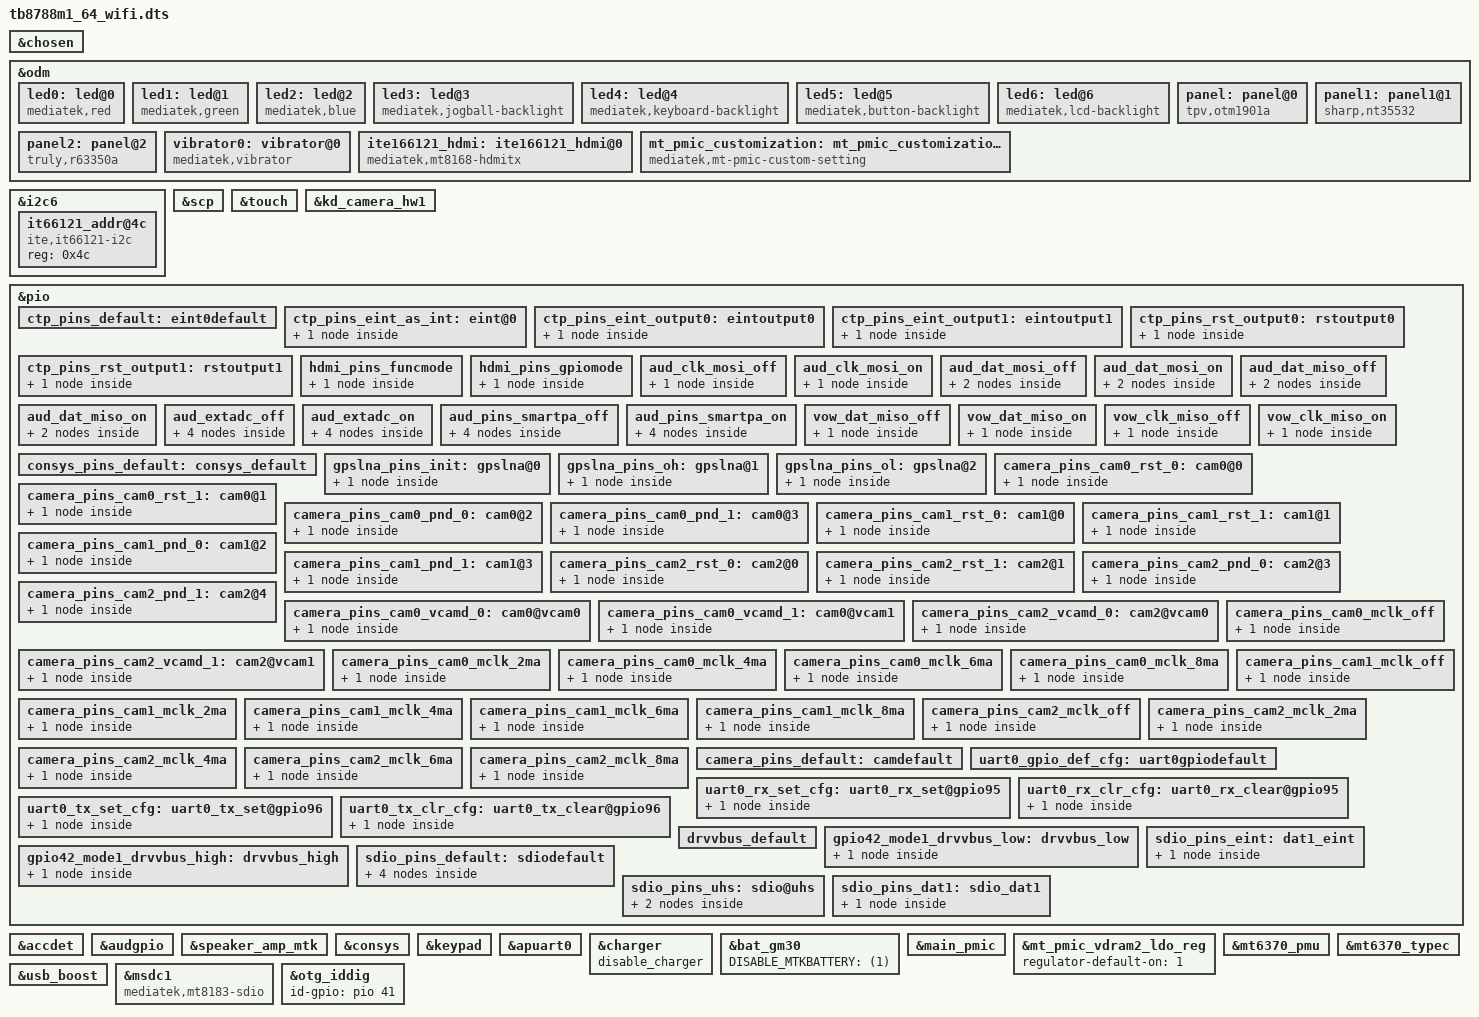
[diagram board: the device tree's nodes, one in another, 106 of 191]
/*
 * Copyright (C) 2019 MediaTek Inc.
 *
 * This program is free software; you can redistribute it and/or modify
 * it under the terms of the GNU General Public License version 2 as
 * published by the Free Software Foundation.
 *
 * This program is distributed in the hope that it will be useful,
 * but WITHOUT ANY WARRANTY; without even the implied warranty of
 * MERCHANTABILITY or FITNESS FOR A PARTICULAR PURPOSE.
 * See http://www.gnu.org/licenses/gpl-2.0.html for more details.
 */

/dts-v1/;
/plugin/;
#include <dt-bindings/interrupt-controller/irq.h>
#include <dt-bindings/interrupt-controller/arm-gic.h>
#include <dt-bindings/pinctrl/mt6771-pinfunc.h>
#include <dt-bindings/clock/mt6771-clk.h>
#include <tb8788m1_64_wifi/cust.dtsi>

/* chosen */
&chosen {
	/* fpga may has no lk, we need to specify display info here */
	/* fb buffer is reserved using this dts by memory node above */

	atag,videolfb-fb_base_l = <0x5e605000>;
	atag,videolfb-fb_base_h = <0x0>;
	atag,videolfb-islcmfound = <1>;
	atag,videolfb-islcm_inited = <0>;
	atag,videolfb-fps= <6000>;
	atag,videolfb-vramSize= <0x017bb000>;
	atag,videolfb-lcmname= "otm1901a_fhd_dsi_vdo_tpv
		r63350a_fhd_dsi_vdo_truly nt35532_fhd_dsi_vdo_sharp";
};

&odm {
	led0:led@0 {
		compatible = "mediatek,red";
		led_mode = <0>;
		data = <1>;
		pwm_config = <0 0 0 0 0>;
	};
	led1:led@1 {
		compatible = "mediatek,green";
		led_mode = <0>;
		data = <1>;
		pwm_config = <0 0 0 0 0>;
	};
	led2:led@2 {
		compatible = "mediatek,blue";
		led_mode = <0>;
		data = <1>;
		pwm_config = <0 0 0 0 0>;
	};
	led3:led@3 {
		compatible = "mediatek,jogball-backlight";
		led_mode = <0>;
		data = <1>;
		pwm_config = <0 0 0 0 0>;
	};
	led4:led@4 {
		compatible = "mediatek,keyboard-backlight";
		led_mode = <0>;
		data = <1>;
		pwm_config = <0 0 0 0 0>;
	};
	led5:led@5 {
		compatible = "mediatek,button-backlight";
		led_mode = <0>;
		data = <1>;
		pwm_config = <0 0 0 0 0>;
	};
	led6:led@6 {
		compatible = "mediatek,lcd-backlight";
		led_mode = <5>;
		data = <1>;
		pwm_config = <0 1 0 0 0>;
	};
	panel: panel@0 {
		compatible = "tpv,otm1901a";
		gpio_lcd_rst = <&pio 45 0>;
		gpio_lcd_pwr_en = <&pio 158 0>;
		gpio_lcd_pwr2_en = <&pio 159 0>;
		gpio_lcd_pwr = <&pio 153 0>;
		status = "okay";
	};
	panel1: panel1@1 {
		compatible = "sharp,nt35532";
		gpio_lcd_rst = <&pio 45 0>;
		gpio_lcd_pwr_en = <&pio 158 0>;
		gpio_lcd_pwr2_en = <&pio 159 0>;
		gpio_lcd_pwr = <&pio 153 0>;
		status = "okay";
	};
	panel2: panel@2 {
		compatible = "truly,r63350a";
		gpio_lcd_rst = <&pio 45 0>;
		gpio_lcd_pwr_en = <&pio 158 0>;
		gpio_lcd_pwr2_en = <&pio 159 0>;
		gpio_lcd_pwr = <&pio 153 0>;
		status = "okay";
	};
	vibrator0:vibrator@0 {
		compatible = "mediatek,vibrator";
		vib_timer = <25>;
		vib_limit = <9>;
		vib_vol= <9>;
	};
	ite166121_hdmi: ite166121_hdmi@0 {
		compatible = "mediatek,mt8168-hdmitx";
	};
	mt_pmic_customization: mt_pmic_customization@0 {
		compatible = "mediatek,mt-pmic-custom-setting";
		custom-reg = <0x1c32 0x1 0x7 0x0 /* LDO_VRF12_OP_EN */
			      0x18ba 0x1 0x1 0x0 /* RG_VPA_NDIS_EN */
		>;
		disable-modem = <1>;
	};
};


&ite166121_hdmi {
	pinctrl-names = "hdmi_poweron", "hdmi_poweroff";
	pinctrl-0 = <&hdmi_pins_funcmode>;
	pinctrl-1 = <&hdmi_pins_gpiomode>;
	vcn33-supply = <&mt_pmic_vcn33_wifi_ldo_reg>;
	vcn18-supply = <&mt_pmic_vcn18_ldo_reg>;
	vrf12-supply = <&mt_pmic_vrf12_ldo_reg>;
	hdmi_power_gpios = <&pio 160 0>;
	status = "okay";
};

&i2c6 {
	status = "okay";
	it66121_addr@4c {
		compatible = "ite,it66121-i2c";
		reg = <0x4c>;
	};
};

&scp {
	core_1 = "enable";
	scp_sramSize = <0x00080000>;     /* scp_A_sram_size */
};

/* TOUCH start */
&touch {
	tpd-resolution = <1080 1920>;
	use-tpd-button = <0>;
	tpd-key-num = <3>;
	tpd-key-local= <139 172 158 0>;
	tpd-key-dim-local = <90 883 100 40
		230 883 100 40 370 883 100 40 0 0 0 0>;
	tpd-max-touch-num = <5>;
	tpd-filter-enable = <1>;
	tpd-filter-pixel-density = <146>;
	tpd-filter-custom-prameters = <0 0 0 0 0 0 0 0 0 0 0 0>;
	tpd-filter-custom-speed = <0 0 0>;
	pinctrl-names = "default", "state_eint_as_int",
		"state_eint_output0", "state_eint_output1",
		"state_rst_output0", "state_rst_output1";
	pinctrl-0 = <&ctp_pins_default>;
	pinctrl-1 = <&ctp_pins_eint_as_int>;
	pinctrl-2 = <&ctp_pins_eint_output0>;
	pinctrl-3 = <&ctp_pins_eint_output1>;
	pinctrl-4 = <&ctp_pins_rst_output0>;
	pinctrl-5 = <&ctp_pins_rst_output1>;
	status = "okay";
};

/* CAMERA specify sensor */
&kd_camera_hw1 {
	cam0_enable_sensor = "ov13855_mipi_raw";
	cam2_enable_sensor = "ov13855main2_mipi_raw";
};
/* CAMERA specify sensor end */

&pio {
	ctp_pins_default: eint0default {
	};
	ctp_pins_eint_as_int: eint@0 {
		pins_cmd_dat {
			pinmux = <PINMUX_GPIO176__FUNC_GPIO176>;
			slew-rate = <0>;
			bias-disable;
		};
	};
	ctp_pins_eint_output0: eintoutput0 {
		pins_cmd_dat {
			pinmux = <PINMUX_GPIO176__FUNC_GPIO176>;
			slew-rate = <1>;
			output-low;
		};
	};
	ctp_pins_eint_output1: eintoutput1 {
		pins_cmd_dat {
			pinmux = <PINMUX_GPIO176__FUNC_GPIO176>;
			slew-rate = <1>;
			output-high;
		};
	};
	ctp_pins_rst_output0: rstoutput0 {
		pins_cmd_dat {
			pinmux = <PINMUX_GPIO177__FUNC_GPIO177>;
			slew-rate = <1>;
			output-low;
		};
	};
	ctp_pins_rst_output1: rstoutput1 {
		pins_cmd_dat {
			pinmux = <PINMUX_GPIO177__FUNC_GPIO177>;
			slew-rate = <1>;
			output-high;
		};
	};
	hdmi_pins_funcmode: hdmi_pins_funcmode {
		pins_cmd_dat {
			pinmux = <PINMUX_GPIO113__FUNC_SCL6>,
				<PINMUX_GPIO114__FUNC_SDA6>,
				<PINMUX_GPIO12__FUNC_I2S5_BCK>,
				<PINMUX_GPIO46__FUNC_I2S5_LRCK>,
				<PINMUX_GPIO47__FUNC_I2S5_DO>,
				<PINMUX_GPIO13__FUNC_DBPI_D0>,
				<PINMUX_GPIO14__FUNC_DBPI_D1>,
				<PINMUX_GPIO15__FUNC_DBPI_D2>,
				<PINMUX_GPIO16__FUNC_DBPI_D3>,
				<PINMUX_GPIO17__FUNC_DBPI_D4>,
				<PINMUX_GPIO18__FUNC_DBPI_D5>,
				<PINMUX_GPIO19__FUNC_DBPI_D6>,
				<PINMUX_GPIO20__FUNC_DBPI_D7>,
				<PINMUX_GPIO21__FUNC_DBPI_D8>,
				<PINMUX_GPIO22__FUNC_DBPI_D9>,
				<PINMUX_GPIO23__FUNC_DBPI_D10>,
				<PINMUX_GPIO24__FUNC_DBPI_D11>,
				<PINMUX_GPIO25__FUNC_DBPI_HSYNC>,
				<PINMUX_GPIO26__FUNC_DBPI_VSYNC>,
				<PINMUX_GPIO27__FUNC_DBPI_DE>,
				<PINMUX_GPIO28__FUNC_DBPI_CK>;
		};
	};
	hdmi_pins_gpiomode: hdmi_pins_gpiomode {
		pins_cmd_dat {
			pinmux = <PINMUX_GPIO113__FUNC_GPIO113>,
				<PINMUX_GPIO114__FUNC_GPIO114>,
				<PINMUX_GPIO12__FUNC_GPIO12>,
				<PINMUX_GPIO46__FUNC_GPIO46>,
				<PINMUX_GPIO47__FUNC_GPIO47>,
				<PINMUX_GPIO13__FUNC_GPIO13>,
				<PINMUX_GPIO14__FUNC_GPIO14>,
				<PINMUX_GPIO15__FUNC_GPIO15>,
				<PINMUX_GPIO16__FUNC_GPIO16>,
				<PINMUX_GPIO17__FUNC_GPIO17>,
				<PINMUX_GPIO18__FUNC_GPIO18>,
				<PINMUX_GPIO19__FUNC_GPIO19>,
				<PINMUX_GPIO20__FUNC_GPIO20>,
				<PINMUX_GPIO21__FUNC_GPIO21>,
				<PINMUX_GPIO22__FUNC_GPIO22>,
				<PINMUX_GPIO23__FUNC_GPIO23>,
				<PINMUX_GPIO24__FUNC_GPIO24>,
				<PINMUX_GPIO25__FUNC_GPIO25>,
				<PINMUX_GPIO26__FUNC_GPIO26>,
				<PINMUX_GPIO27__FUNC_GPIO27>,
				<PINMUX_GPIO28__FUNC_GPIO28>;
		};
	};
};
/* TOUCH end */

/* accdet start */
&accdet {
	/* accdet micbias voltage: 0x07,2.7v;0x05,2.5v;0x02,1.9v */
	accdet-mic-vol = <6>;
	headset-mode-setting = <0x500 0x500 1 0x1f0 0x800 0x800 0x20 0x44>;
	accdet-plugout-debounce = <1>;
	/*1:ACC mode, 2:low cost without in bias, 6:low cost with in bias*/
	accdet-mic-mode = <2>;
	/* eint_level_trigger: 8,LEVEL_LOW(default);*/
	/* 4,LEVEL_HIGH;others,LEVEL_LOW */
	headset-eint-level-pol = <4>;
	/*0--MD_MAX--UP_MAX--DW_MAX*/
	headset-three-key-threshold = <0 80 220 400>;
	headset-three-key-threshold-CDD = <0 121 192 600>;
	/*0--MD_MAX--VOICE_MAX--UP_MAX--DW_MAX*/
	headset-four-key-threshold = <0 58 121 192 400>;
	status = "okay";
};
/* accdet end */

/* AUDIO GPIO standardization */
&audgpio {
	pinctrl-names = "aud_clk_mosi_off",
			"aud_clk_mosi_on",
			"aud_dat_mosi_off",
			"aud_dat_mosi_on",
			"aud_dat_miso_off",
			"aud_dat_miso_on",
			"aud_extadc_off",
			"aud_extadc_on",
			"aud_smartpa_off",
			"aud_smartpa_on",
			"vow_dat_miso_off",
			"vow_dat_miso_on",
			"vow_clk_miso_off",
			"vow_clk_miso_on";
	pinctrl-0 = <&aud_clk_mosi_off>;
	pinctrl-1 = <&aud_clk_mosi_on>;
	pinctrl-2 = <&aud_dat_mosi_off>;
	pinctrl-3 = <&aud_dat_mosi_on>;
	pinctrl-4 = <&aud_dat_miso_off>;
	pinctrl-5 = <&aud_dat_miso_on>;
	pinctrl-6 = <&aud_extadc_off>;
	pinctrl-7 = <&aud_extadc_on>;
	pinctrl-8 = <&aud_pins_smartpa_off>;
	pinctrl-9 = <&aud_pins_smartpa_on>;
	pinctrl-10 = <&vow_dat_miso_off>;
	pinctrl-11 = <&vow_dat_miso_on>;
	pinctrl-12 = <&vow_clk_miso_off>;
	pinctrl-13 = <&vow_clk_miso_on>;
	status = "okay";
};

&pio {
	aud_clk_mosi_off: aud_clk_mosi_off {
		pins_cmd0_dat {
			pinmux = <PINMUX_GPIO136__FUNC_GPIO136>;
		};
	};

	aud_clk_mosi_on: aud_clk_mosi_on {
		pins_cmd0_dat {
			pinmux = <PINMUX_GPIO136__FUNC_AUD_CLK_MOSI>;
		};
	};

	aud_dat_mosi_off: aud_dat_mosi_off {
		pins_cmd1_dat {
			pinmux = <PINMUX_GPIO138__FUNC_GPIO138>;
		};
		pins_cmd2_dat {
			pinmux = <PINMUX_GPIO139__FUNC_GPIO139>;
		};
	};

	aud_dat_mosi_on: aud_dat_mosi_on {
		pins_cmd1_dat {
			pinmux = <PINMUX_GPIO138__FUNC_AUD_DAT_MOSI0>;
		};
		pins_cmd2_dat {
			pinmux = <PINMUX_GPIO139__FUNC_AUD_DAT_MOSI1>;
		};
	};

	aud_dat_miso_off: aud_dat_miso_off {
		pins_cmd1_dat {
			pinmux = <PINMUX_GPIO142__FUNC_GPIO142>;
		};
		pins_cmd2_dat {
			pinmux = <PINMUX_GPIO143__FUNC_GPIO143>;
		};
	};

	aud_dat_miso_on: aud_dat_miso_on {
		pins_cmd1_dat {
			pinmux = <PINMUX_GPIO142__FUNC_AUD_DAT_MISO0>;
		};
		pins_cmd2_dat {
			pinmux = <PINMUX_GPIO143__FUNC_AUD_DAT_MISO1>;
		};
	};

	aud_extadc_off: aud_extadc_off {
		pins_cmd0_dat {
			pinmux = <PINMUX_GPIO98__FUNC_GPIO98>;
		};
		pins_cmd1_dat {
			pinmux = <PINMUX_GPIO101__FUNC_GPIO101>;
		};
		pins_cmd2_dat {
			pinmux = <PINMUX_GPIO102__FUNC_GPIO102>;
		};
		pins_cmd3_dat {
			pinmux = <PINMUX_GPIO174__FUNC_GPIO174>;
		};
	};

	aud_extadc_on: aud_extadc_on {
		pins_cmd0_dat {
			pinmux = <PINMUX_GPIO98__FUNC_I2S2_BCK>;
		};
		pins_cmd1_dat {
			pinmux = <PINMUX_GPIO101__FUNC_I2S2_LRCK>;
		};
		pins_cmd2_dat {
			pinmux = <PINMUX_GPIO102__FUNC_I2S2_DI>;
		};
		pins_cmd3_dat {
			pinmux = <PINMUX_GPIO174__FUNC_I2S2_DI2>;
		};
	};

	aud_pins_smartpa_off: aud_pins_smartpa_off {
		pins_cmd0_dat {
			pinmux = <PINMUX_GPIO170__FUNC_GPIO170>;
		};
		pins_cmd1_dat {
			pinmux = <PINMUX_GPIO171__FUNC_GPIO171>;
		};
		pins_cmd2_dat {
			pinmux = <PINMUX_GPIO172__FUNC_GPIO172>;
		};
		pins_cmd3_dat {
			pinmux = <PINMUX_GPIO173__FUNC_GPIO173>;
		};
	};

	aud_pins_smartpa_on: aud_pins_smartpa_on {
		pins_cmd0_dat {
			pinmux = <PINMUX_GPIO170__FUNC_I2S1_BCK>;
		};
		pins_cmd1_dat {
			pinmux = <PINMUX_GPIO171__FUNC_I2S1_LRCK>;
		};
		pins_cmd2_dat {
			pinmux= <PINMUX_GPIO172__FUNC_I2S1_DO>;
		};
		pins_cmd3_dat {
			pinmux = <PINMUX_GPIO173__FUNC_I2S1_MCK>;
		};
	};

	vow_dat_miso_off: vow_dat_miso_off {
		pins_cmd1_dat {
			pinmux = <PINMUX_GPIO142__FUNC_GPIO142>;
		};
	};

	vow_dat_miso_on: vow_dat_miso_on {
		pins_cmd1_dat {
			pinmux = <PINMUX_GPIO142__FUNC_VOW_DAT_MISO>;
		};
	};

	vow_clk_miso_off: vow_clk_miso_off {
		pins_cmd3_dat {
			pinmux = <PINMUX_GPIO143__FUNC_GPIO143>;
		};
	};

	vow_clk_miso_on: vow_clk_miso_on {
		pins_cmd3_dat {
			pinmux = <PINMUX_GPIO143__FUNC_VOW_CLK_MISO>;
		};
	};
};

&speaker_amp_mtk{
	rst_gpio = <&pio 151 0>;
	power_gpio = <&pio 150 0>;
};
/* AUDIO end */

/* CONSYS GPIO standardization */
&pio {
	consys_pins_default: consys_default {
	};
	gpslna_pins_init: gpslna@0 {
		pins_cmd_dat {
			pinmux = <PINMUX_GPIO155__FUNC_GPIO155>;
			slew-rate = <0>;
			bias-disable;
			output-low;
		};
	};
	gpslna_pins_oh: gpslna@1 {
		pins_cmd_dat {
			pinmux = <PINMUX_GPIO155__FUNC_GPIO155>;
			slew-rate = <1>;
			output-high;
		};
	};
	gpslna_pins_ol: gpslna@2 {
		pins_cmd_dat {
			pinmux = <PINMUX_GPIO155__FUNC_GPIO155>;
			slew-rate = <1>;
			output-low;
		};
	};
};
&consys {
	pinctrl-names = "default", "gps_lna_state_init",
		"gps_lna_state_oh", "gps_lna_state_ol";
	pinctrl-0 = <&consys_pins_default>;
	pinctrl-1 = <&gpslna_pins_init>;
	pinctrl-2 = <&gpslna_pins_oh>;
	pinctrl-3 = <&gpslna_pins_ol>;
	status = "okay";
};
/* CONSYS end */

/* CAMERA GPIO standardization */
&pio {
	camera_pins_cam0_rst_0: cam0@0 {
		pins_cmd_dat {
			pinmux = <PINMUX_GPIO37__FUNC_GPIO37>;
			slew-rate = <1>; /*direction 0:in, 1:out*/
			output-low;/*direction out used only.*/
					/*output_low or high*/
		};
	};
	camera_pins_cam0_rst_1: cam0@1 {
		pins_cmd_dat {
			pinmux = <PINMUX_GPIO37__FUNC_GPIO37>;
			slew-rate = <1>;
			output-high;
		};
	};
	camera_pins_cam0_pnd_0: cam0@2 {
		pins_cmd_dat {
			pinmux = <PINMUX_GPIO35__FUNC_GPIO35>;
			slew-rate = <1>;
			output-low;
		};
	};
	camera_pins_cam0_pnd_1: cam0@3 {
		pins_cmd_dat {
			pinmux = <PINMUX_GPIO35__FUNC_GPIO35>;
			slew-rate = <1>;
			output-high;
		};
	};
	camera_pins_cam1_rst_0: cam1@0 {
		pins_cmd_dat {
			pinmux = <PINMUX_GPIO36__FUNC_GPIO36>;
			slew-rate = <1>; /*direction 0:in, 1:out*/
			output-low;/*direction out used only.*/
					/*output_low or high*/
		};
	};
	camera_pins_cam1_rst_1: cam1@1 {
		pins_cmd_dat {
			pinmux = <PINMUX_GPIO36__FUNC_GPIO36>;
			slew-rate = <1>;
			output-high;
		};
	};
	camera_pins_cam1_pnd_0: cam1@2 {
		pins_cmd_dat {
			pinmux = <PINMUX_GPIO38__FUNC_GPIO38>;
			slew-rate = <1>;
			output-low;
		};
	};
	camera_pins_cam1_pnd_1: cam1@3 {
		pins_cmd_dat {
			pinmux = <PINMUX_GPIO38__FUNC_GPIO38>;
			slew-rate = <1>;
			output-high;
		};
	};
	camera_pins_cam2_rst_0: cam2@0 {
		pins_cmd_dat {
			pinmux = <PINMUX_GPIO109__FUNC_GPIO109>;
			slew-rate = <1>;
			output-low;
		};
	};
	camera_pins_cam2_rst_1: cam2@1 {
		pins_cmd_dat {
			pinmux = <PINMUX_GPIO109__FUNC_GPIO109>;
			slew-rate = <1>;
			output-high;
		};
	};
	camera_pins_cam2_pnd_0: cam2@3 {
		pins_cmd_dat {
			pinmux = <PINMUX_GPIO107__FUNC_GPIO107>;
			slew-rate = <1>;
			output-low;
		};
	};
	camera_pins_cam2_pnd_1: cam2@4 {
		pins_cmd_dat {
			pinmux = <PINMUX_GPIO107__FUNC_GPIO107>;
			slew-rate = <1>;
			output-high;
		};
	};
	camera_pins_cam0_vcamd_0: cam0@vcam0 {
		pins_cmd_dat {
			pinmux = <PINMUX_GPIO40__FUNC_GPIO40>;
			slew-rate = <1>;
			output-low;
		};
	};
	camera_pins_cam0_vcamd_1: cam0@vcam1 {
		pins_cmd_dat {
			pinmux = <PINMUX_GPIO40__FUNC_GPIO40>;
			slew-rate = <1>;
			output-high;
		};
	};
	camera_pins_cam2_vcamd_0: cam2@vcam0 {
		pins_cmd_dat {
			pinmux = <PINMUX_GPIO39__FUNC_GPIO39>;
			slew-rate = <1>;
			output-low;
		};
	};
	camera_pins_cam2_vcamd_1: cam2@vcam1 {
		pins_cmd_dat {
			pinmux = <PINMUX_GPIO39__FUNC_GPIO39>;
			slew-rate = <1>;
			output-high;
		};
	};
	camera_pins_cam0_mclk_off: camera_pins_cam0_mclk_off {
		pins_cmd_dat {
			pinmux = <PINMUX_GPIO99__FUNC_GPIO99>;
			drive-strength = <1>;
		};
	};
	camera_pins_cam0_mclk_2ma: camera_pins_cam0_mclk_2ma {
		pins_cmd_dat {
			pinmux = <PINMUX_GPIO99__FUNC_CMMCLK0>;
			drive-strength = <0>;
		};
	};
	camera_pins_cam0_mclk_4ma: camera_pins_cam0_mclk_4ma {
		pins_cmd_dat {
			pinmux = <PINMUX_GPIO99__FUNC_CMMCLK0>;
			drive-strength = <1>;
		};
	};
	camera_pins_cam0_mclk_6ma: camera_pins_cam0_mclk_6ma {
		pins_cmd_dat {
			pinmux = <PINMUX_GPIO99__FUNC_CMMCLK0>;
			drive-strength = <2>;
		};
	};
	camera_pins_cam0_mclk_8ma: camera_pins_cam0_mclk_8ma {
		pins_cmd_dat {
			pinmux = <PINMUX_GPIO99__FUNC_CMMCLK0>;
			drive-strength = <3>;
		};
	};
	camera_pins_cam1_mclk_off: camera_pins_cam1_mclk_off {
		pins_cmd_dat {
			pinmux = <PINMUX_GPIO100__FUNC_GPIO100>;
			drive-strength = <1>;
		};
	};
	camera_pins_cam1_mclk_2ma: camera_pins_cam1_mclk_2ma {
		pins_cmd_dat {
			pinmux = <PINMUX_GPIO100__FUNC_CMMCLK1>;
			drive-strength = <0>;
		};
	};
	camera_pins_cam1_mclk_4ma: camera_pins_cam1_mclk_4ma {
		pins_cmd_dat {
			pinmux = <PINMUX_GPIO100__FUNC_CMMCLK1>;
			drive-strength = <1>;
		};
	};
	camera_pins_cam1_mclk_6ma: camera_pins_cam1_mclk_6ma {
		pins_cmd_dat {
			pinmux = <PINMUX_GPIO100__FUNC_CMMCLK1>;
			drive-strength = <2>;
		};
	};
	camera_pins_cam1_mclk_8ma: camera_pins_cam1_mclk_8ma {
		pins_cmd_dat {
			pinmux = <PINMUX_GPIO100__FUNC_CMMCLK1>;
			drive-strength = <3>;
		};
	};
	camera_pins_cam2_mclk_off: camera_pins_cam2_mclk_off {
		pins_cmd_dat {
			pinmux = <PINMUX_GPIO108__FUNC_GPIO108>;
			drive-strength = <1>;
		};
	};
	camera_pins_cam2_mclk_2ma: camera_pins_cam2_mclk_2ma {
		pins_cmd_dat {
			pinmux = <PINMUX_GPIO108__FUNC_CMMCLK2>;
			drive-strength = <0>;
		};
	};
	camera_pins_cam2_mclk_4ma: camera_pins_cam2_mclk_4ma {
		pins_cmd_dat {
			pinmux = <PINMUX_GPIO108__FUNC_CMMCLK2>;
			drive-strength = <1>;
		};
	};
	camera_pins_cam2_mclk_6ma: camera_pins_cam2_mclk_6ma {
		pins_cmd_dat {
			pinmux = <PINMUX_GPIO108__FUNC_CMMCLK2>;
			drive-strength = <2>;
		};
	};
	camera_pins_cam2_mclk_8ma: camera_pins_cam2_mclk_8ma {
		pins_cmd_dat {
			pinmux = <PINMUX_GPIO108__FUNC_CMMCLK2>;
			drive-strength = <3>;
		};
	};
	camera_pins_default: camdefault {
	};
};
&kd_camera_hw1 {
	pinctrl-names = "default",
			"cam0_rst0", "cam0_rst1",
			"cam0_pnd0", "cam0_pnd1",
			"cam1_rst0", "cam1_rst1",
			"cam1_pnd0", "cam1_pnd1",
			"cam2_rst0", "cam2_rst1",
			"cam2_pnd0", "cam2_pnd1",
			"cam_ldo_vcamd_0", "cam_ldo_vcamd_1",
			"cam_ldo_main2_vcamd_0", "cam_ldo_main2_vcamd_1",
			"cam0_mclk_off",
			"cam0_mclk_2mA", "cam0_mclk_4mA",
			"cam0_mclk_6mA", "cam0_mclk_8mA",
			"cam1_mclk_off",
			"cam1_mclk_2mA", "cam1_mclk_4mA",
			"cam1_mclk_6mA", "cam1_mclk_8mA",
			"cam2_mclk_off",
			"cam2_mclk_2mA", "cam2_mclk_4mA",
			"cam2_mclk_6mA", "cam2_mclk_8mA";
	pinctrl-0 = <&camera_pins_default>;
	pinctrl-1 = <&camera_pins_cam0_rst_0>;
	pinctrl-2 = <&camera_pins_cam0_rst_1>;
	pinctrl-3 = <&camera_pins_cam0_pnd_0>;
	pinctrl-4 = <&camera_pins_cam0_pnd_1>;
	pinctrl-5 = <&camera_pins_cam1_rst_0>;
	pinctrl-6 = <&camera_pins_cam1_rst_1>;
	pinctrl-7 = <&camera_pins_cam1_pnd_0>;
	pinctrl-8 = <&camera_pins_cam1_pnd_1>;
	pinctrl-9 = <&camera_pins_cam2_rst_0>;
	pinctrl-10 = <&camera_pins_cam2_rst_1>;
	pinctrl-11 = <&camera_pins_cam2_pnd_0>;
	pinctrl-12 = <&camera_pins_cam2_pnd_1>;
	pinctrl-13 = <&camera_pins_cam0_vcamd_0>;
	pinctrl-14 = <&camera_pins_cam0_vcamd_1>;
	pinctrl-15 = <&camera_pins_cam2_vcamd_0>;
	pinctrl-16 = <&camera_pins_cam2_vcamd_1>;
	pinctrl-17 = <&camera_pins_cam0_mclk_off>;
	pinctrl-18 = <&camera_pins_cam0_mclk_2ma>;
	pinctrl-19 = <&camera_pins_cam0_mclk_4ma>;
	pinctrl-20 = <&camera_pins_cam0_mclk_6ma>;
	pinctrl-21 = <&camera_pins_cam0_mclk_8ma>;
	pinctrl-22 = <&camera_pins_cam1_mclk_off>;
	pinctrl-23 = <&camera_pins_cam1_mclk_2ma>;
	pinctrl-24 = <&camera_pins_cam1_mclk_4ma>;
	pinctrl-25 = <&camera_pins_cam1_mclk_6ma>;
	pinctrl-26 = <&camera_pins_cam1_mclk_8ma>;
	pinctrl-27 = <&camera_pins_cam2_mclk_off>;
	pinctrl-28 = <&camera_pins_cam2_mclk_2ma>;
	pinctrl-29 = <&camera_pins_cam2_mclk_4ma>;
	pinctrl-30 = <&camera_pins_cam2_mclk_6ma>;
	pinctrl-31 = <&camera_pins_cam2_mclk_8ma>;
	status = "okay";
};

&keypad {
	mediatek,kpd-key-debounce = <1024>;
	mediatek,kpd-sw-pwrkey = <116>;
	mediatek,kpd-hw-pwrkey = <8>;
	mediatek,kpd-sw-rstkey  = <0>;
	mediatek,kpd-hw-rstkey = <17>;
	mediatek,kpd-use-extend-type = <0>;
	/*HW Keycode [0~71] -> Linux Keycode*/
	mediatek,kpd-hw-map-num = <72>;
	mediatek,kpd-hw-init-map =
			<115 0 0 0 0 0 0 0 0 114 0 0 0 0 0 0 0 0 0 0 0 0 0 0
			0 0 0 0 0 0 0 0 0 0 0 0 0 0 0 0 0 0 0 0 0 0 0 0
			0 0 0 0 0 0 0 0 0 0 0 0 0 0 0 0 0 0 0 0 0 0 0 0 >;
	mediatek,kpd-pwrkey-eint-gpio = <0>;
	mediatek,kpd-pwkey-gpio-din  = <0>;
	mediatek,kpd-hw-dl-key0 = <0>;
	mediatek,kpd-hw-dl-key1 = <9>;
	mediatek,kpd-hw-dl-key2 = <17>;
	mediatek,kpd-hw-recovery-key = <0>;
	mediatek,kpd-hw-factory-key  = <9>;
};

/* UART GPIO */
&apuart0 {
	pinctrl-names = "uart0_gpio_default",
			"uart0_rx_set",
			"uart0_rx_clear",
			"uart0_tx_set",
			"uart0_tx_clear";
	pinctrl-0 = <&uart0_gpio_def_cfg>;
	pinctrl-1 = <&uart0_rx_set_cfg>;
	pinctrl-2 = <&uart0_rx_clr_cfg>;
	pinctrl-3 = <&uart0_tx_set_cfg>;
	pinctrl-4 = <&uart0_tx_clr_cfg>;
	status = "okay";
};

&pio {
	/* UART GPIO Settings - Start */
	/* UART0: rx set, rx clear, tx clear, tx clear*/
	uart0_gpio_def_cfg:uart0gpiodefault {

	};
	uart0_rx_set_cfg:uart0_rx_set@gpio95 {
		pins_cmd_dat {
			pinmux = <PINMUX_GPIO95__FUNC_URXD0>;
		};
	};
	uart0_rx_clr_cfg:uart0_rx_clear@gpio95 {
		pins_cmd_dat {
			pinmux = <PINMUX_GPIO95__FUNC_GPIO95>;
			slew-rate = <1>;
			output-high;
		};
	};
	uart0_tx_set_cfg:uart0_tx_set@gpio96 {
		pins_cmd_dat {
			pinmux = <PINMUX_GPIO96__FUNC_UTXD0>;
		};
	};
	uart0_tx_clr_cfg:uart0_tx_clear@gpio96 {
		pins_cmd_dat {
			pinmux = <PINMUX_GPIO96__FUNC_GPIO96>;
			slew-rate = <1>;
			output-high;
		};
	};
};/* UART GPIO end */

&charger {
	disable_charger;
};

&bat_gm30 {
	DISABLE_MTKBATTERY = <(1)>;
};

&main_pmic {
	interrupt-parent = <&pio>;
	interrupts = <182 IRQ_TYPE_LEVEL_HIGH 190 0>;
	status = "okay";
};

&mt_pmic_vdram2_ldo_reg {
	regulator-default-on = <1>;
};

&mt6370_pmu {
	mt6370,intr_gpio_num = <10>; /* direct defined GPIO num */
	mt6370,intr_gpio = <&pio 10 0x0>;
};

&mt6370_typec {
	mt6370pd,intr_gpio_num = <41>; /* direct defined GPIO num */
	mt6370pd,intr_gpio = <&pio 41 0x0>;
};

/* USB Setting -Start */
&pio {
	drvvbus_default: drvvbus_default {
	};

	gpio42_mode1_drvvbus_low: drvvbus_low {
		pins_cmd_dat {
			pinmux = <PINMUX_GPIO42__FUNC_GPIO42>;
			slew-rate = <1>;
			output-low;
		};
	};
	gpio42_mode1_drvvbus_high: drvvbus_high {
		pins_cmd_dat {
			pinmux = <PINMUX_GPIO42__FUNC_GPIO42>;
			slew-rate = <1>;
			output-high;
		};
	};
};

&usb_boost {
	pinctrl-names =	"drvvbus_default", "drvvbus_low", "drvvbus_high";
	pinctrl-0 = <&drvvbus_default>;
	pinctrl-1 = <&gpio42_mode1_drvvbus_low>;
	pinctrl-2 = <&gpio42_mode1_drvvbus_high>;
	status = "okay";
};

&msdc1 {
	compatible = "mediatek,mt8183-sdio";
	reg = <0x0 0x11240000 0x0 0x10000>,
	    <0 0x11e10000 0 0x1000>;
	clocks = <&infracfg_ao INFRACFG_AO_MSDC1_SCK_CG>,
	       <&infracfg_ao INFRACFG_AO_MSDC1_CG>;
	clock-names = "source", "hclk";
	status = "okay";
	eint-gpios = <&pio 34 0>;
	bus-width = <4>;
	max-frequency = <200000000>;
	cap-sd-highspeed;
	sd-uhs-sdr50;
	sd-uhs-sdr104;
	pinctrl-names = "state_eint", "default", "state_uhs", "state_dat1";
	pinctrl-0 = <&sdio_pins_eint>;
	pinctrl-1 = <&sdio_pins_default>;
	pinctrl-2 = <&sdio_pins_uhs>;
	pinctrl-3 = <&sdio_pins_dat1>;
	keep-power-in-suspend;
	enable-sdio-wakeup;
	cap-sdio-irq;
	non-removable;
	vmmc-supply = <&mt_pmic_vmch_ldo_reg>;
	vqmmc-supply = <&mt_pmic_vmc_ldo_reg>;
};

&pio {
	sdio_pins_eint: dat1_eint {
		pins_dat1 {
			pinmux = <PINMUX_GPIO34__FUNC_GPIO34>;
			input_enable;
			slew-rate = <0>;
			bias-pull-up = <MTK_PUPD_SET_R1R0_01>;
		};
	};

	sdio_pins_default: sdiodefault {
		pins_cmd_dat {
			pinmux = <PINMUX_GPIO31__FUNC_MSDC1_CMD>,
			       <PINMUX_GPIO32__FUNC_MSDC1_DAT0>,
			       <PINMUX_GPIO34__FUNC_MSDC1_DAT1>,
			       <PINMUX_GPIO33__FUNC_MSDC1_DAT2>,
			       <PINMUX_GPIO30__FUNC_MSDC1_DAT3>;
			bias-pull-up = <MTK_PUPD_SET_R1R0_01>;
			drive-strength = <4>;
			output-high;
		};

		pins_clk {
			pinmux = <PINMUX_GPIO29__FUNC_MSDC1_CLK>;
			bias-pull-down = <MTK_PUPD_SET_R1R0_10>;
			drive-strength = <4>;
			output-low;
		};

		pins_pmu_en {
			pinmux = <PINMUX_GPIO178__FUNC_GPIO178>;
			output-high;
		};
		pins_dev_rst {
			pinmux = <PINMUX_GPIO166__FUNC_GPIO166>;
			output-high;
		};
	};

	sdio_pins_uhs: sdio@uhs {
		pins_cmd_dat {
			pinmux = <PINMUX_GPIO31__FUNC_MSDC1_CMD>,
			       <PINMUX_GPIO32__FUNC_MSDC1_DAT0>,
			       <PINMUX_GPIO34__FUNC_MSDC1_DAT1>,
			       <PINMUX_GPIO33__FUNC_MSDC1_DAT2>,
			       <PINMUX_GPIO30__FUNC_MSDC1_DAT3>;
			bias-pull-up = <MTK_PUPD_SET_R1R0_01>;
			drive-strength = <4>;
			output-high;
		};

		pins_clk {
			pinmux = <PINMUX_GPIO29__FUNC_MSDC1_CLK>;
			bias-pull-down = <MTK_PUPD_SET_R1R0_10>;
			drive-strength = <4>;
			output-low;
		};
	};

	sdio_pins_dat1: sdio_dat1 {
		pins_dat1 {
			pinmux = <PINMUX_GPIO34__FUNC_MSDC1_DAT1>;
			drive-strength = <4>;
			bias-pull-up = <MTK_PUPD_SET_R1R0_01>;
			output-high;
		};
	};
};

&otg_iddig {
	id-gpio = <&pio 41 0>;
};
/* USB Setting -End */

/*End of this file, DO NOT ADD ANYTHING HERE*/

